# FM33L0XX register map
File version: 1.0
CPU: SC000 r1p0, little endian, no MPU, no FPU, 3 interrupt priority bits
Registers are 32-bit, read-write, reset 0x0 unless marked. A register's access mark holds for its fields unless they carry their own. Offsets are from the block's base; [hi:lo] are bit positions.

## PMU — POWER MANAGEMENT UNIT
Base 0x40000100
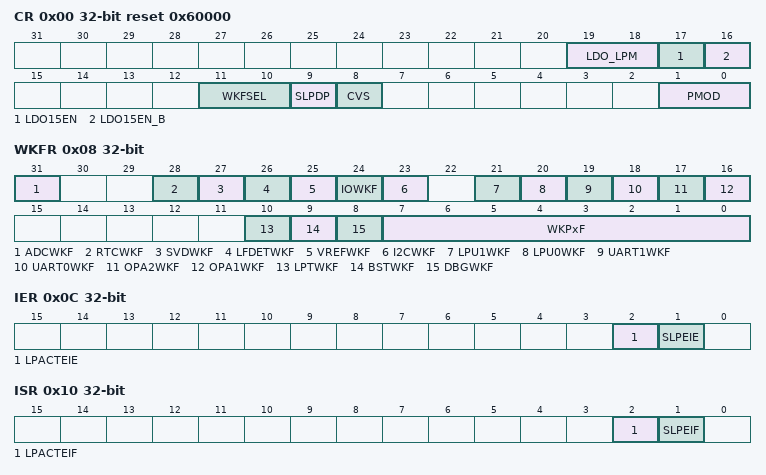
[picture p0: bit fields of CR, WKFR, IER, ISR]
0x00 CR reset 0x60000 — Low Power Management Config Register
  [19:18] LDO_LPM — LDO Low Power Config
    0=NOMAL MODE; 1=NOMAL MODE; 2=LOW POWER MODE; 3=NOMAL MODE
  [17] LDO15EN ro — LDO15 enable status
    0=DISABLE (LDO15 SHUT DOWN); 1=ENABLE (LDO15 ENABLE)
  [16] LDO15EN_B ro — LDO15 ENABLE BIT REVERSE
    0=ENABLE (ldo15 enable); 1=shutdown (ldo15 shutdown)
  [11:10] WKFSEL — Sleep Wakeup Frequency
    0=RCHF-8M; 1=RCHF-16M; 2=RCHF-24M; 3=RFU (RCHF-24M)
  [9] SLPDP — DeepSleep config
    0=Sleep mode; 1=DeepSleep mode,close vref
  [8] CVS — Core Voltage Scaling
    0=NOScaling (NOT Scaling at Sleep/DeepSleep/Stop mode); 1=Scaling to 1.2V at Sleep/DeepSleep/Stop mode
  [1:0] PMOD — power down mode
    0=Active mode; 1=LPRUN mode; 2=Sleep mode
0x04 WKTR reset 0x1 — Wakeup Delay Control Register
  [1:0] TRHR — TIME OF RHR AT DeepSleep/Stop
    0=0us (time of RHR is 0us); 1=4us (time of RHR is 4us); 2=8us (time of RHR is 8us); 3=16us (time of RHR is 16us)
0x08 WKFR — IO Wakeup FLAG Register
  [31] ADCWKF ro — adc wakeup flag
    0=NOADCWK (no adc wakeup); 1=ADCWK (adc wakeup)
  [28] RTCWKF ro — rtc wakeup flag
    0=NORTCWK (no rtc wakeup); 1=RTCWK (rtc wakeup)
  [27] SVDWKF ro — svd wakeup flag
    0=NOSVDWK (no svd wakeup); 1=SVDWK (svd wakeup)
  [26] LFDETWKF ro — lfdet wakeup flag
    0=NOLFDETWK (no lfdet wakeup); 1=LFDETWK (lfdet wakeup)
  [25] VREFWKF ro — vref wakeup flag
    0=NOVREFWK (no vref wakeup); 1=VREFWK (vref wakeup)
  [24] IOWKF ro — io wakeup flag
    0=NOIOWK (no io wakeup); 1=IOWK (io wakeup)
  [23] I2CWKF ro — i2c wakeup flag
    0=NOI2CWK (no i2c wakeup); 1=I2CWK (i2c wakeup)
  [21] LPU1WKF ro — lpuart1 wakeup flag
    0=NOLPUART1WK (no lpuart1 wakeup); 1=LPUART1WK (lpuart1 wakeup)
  [20] LPU0WKF ro — lpuart0 wakeup flag
    0=NOLPUART0WK (no lpuart0 wakeup); 1=LPUART0WK (lpuart0 wakeup)
  [19] UART1WKF ro — uart1 wakeup flag
    0=NOUART1WK (no uart1 wakeup); 1=UART1WK (uart1 wakeup)
  [18] UART0WKF ro — uart0 wakeup flag
    0=NOUART0WK (no uart0 wakeup); 1=UART0WK (uart0 wakeup)
  [17] OPA2WKF ro — opa2 wakeup flag
    0=NOOPA2WK (no opa2 wakeup); 1=OPA2WK (opa2 wakeup)
  [16] OPA1WKF ro — opa1 wakeup flag
    0=NOOPA1WK (no opa1 wakeup); 1=OPA1WK (opa1 wakeup)
  [10] LPTWKF ro — lptim wakeup flag
    0=NOLPTWK (no lptim wakeup); 1=LPTWK (lptim wakeup)
  [9] BSTWKF ro — btim wakeup flag
    0=NOBTWK (no btim wakeup); 1=BTWK (btim wakeup)
  [8] DBGWKF — debug wakeup flag,write 1 to clear
    0=NODBWK (no debug wakeup); 1=DBWK (debug wakeup)
  [7:0] WKPxF — wakeup flag of pinX
0x0C IER — low power IE register
  [2] LPACTEIE — lp active error interrupt enable bit
    0=DISABLE (disable lp active error interupt); 1=ENABLE (lp active error interrupt enable)
  [1] SLPEIE — sleep error interrupt enable bit
    0=DISABLE (disable Sleep error interrupt); 1=ENABLE (Enable sleep error interrupt)
0x10 ISR — low power interrupt flag register
  [2] LPACTEIF — go into lp active error flag
    0=LPACTIVE_OK (go into lp active ok); 1=LPACTIVE_ERROR (go into lp active error)
  [1] SLPEIF — sleep error interrupt error
    0=SLPE_OK (go into sleep ok); 1=SLPE_ERR (go into sleep error)

## PMU_VREF — POWER VERF MANAGEMENT UNIT
Base 0x4001280C
0x00 CR — Low Power VERF Config Register
  [0] EN — VREF Enable
    0=Disable (Vref1p2 Disable); 1=Enable (Vref1p2 Enable)
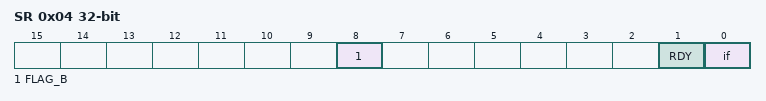
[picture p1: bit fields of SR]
0x04 SR — VREF1p22 FLAG Register
  [all] fields
    0=no set (VREF1p22 is not set); 1=set (VREF1p22 is set)
  [8] FLAG_B ro — VVREF stable Flag from analog
  [1] RDY ro — VREF Ready
  [0] if — VREF Ready Flag
0x08 IER — IVREF Interrupt Enable Register
  [0] IE — VREF Interrupt Enable Register
    0=Disable (Interrupt Disable); 1=Enable (Interrupt Enable)
